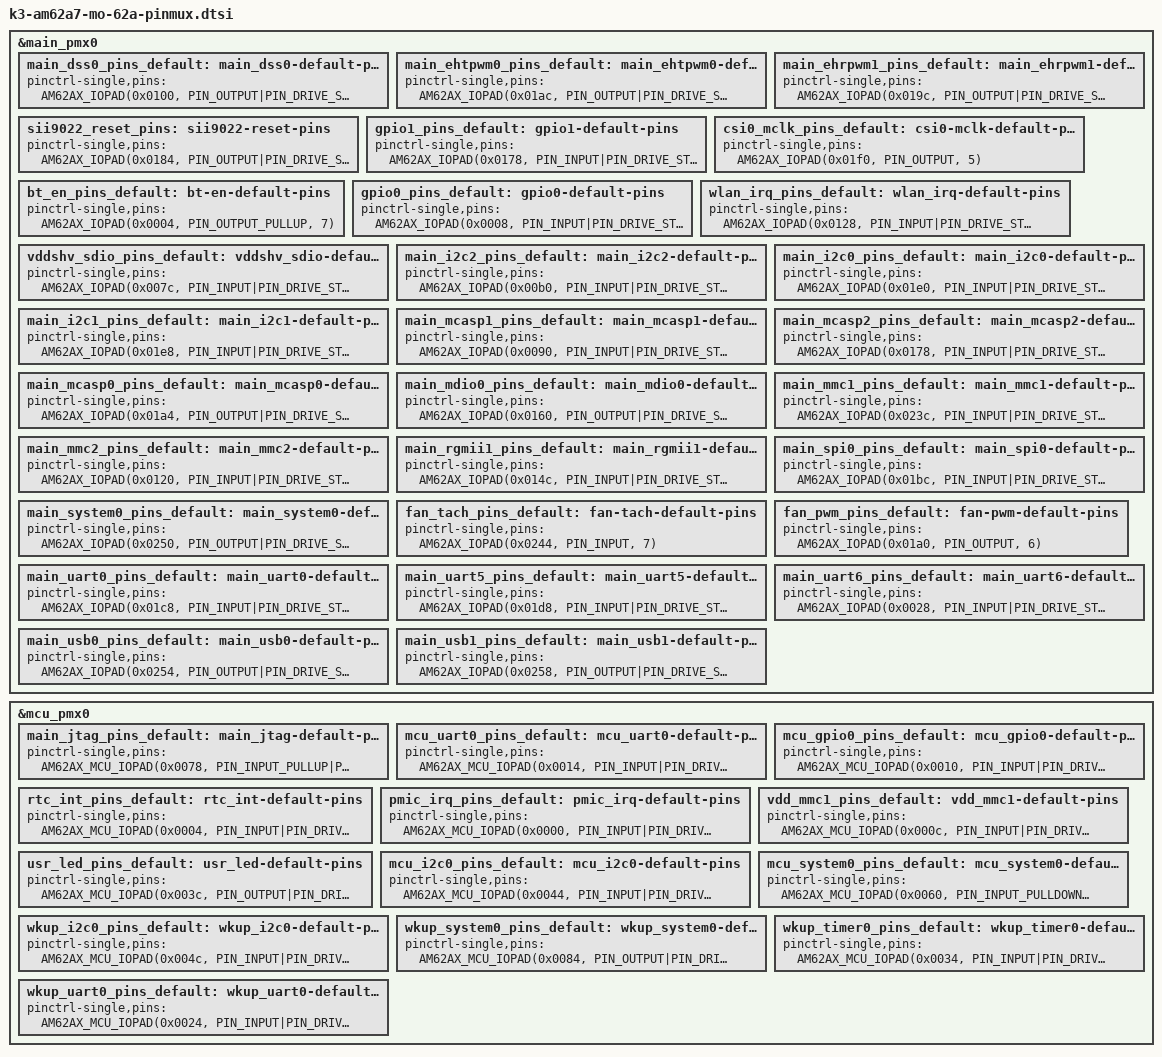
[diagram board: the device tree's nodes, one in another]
/* This file was auto-generated by TI PinMux on 2026/1/26 at 15:44:53. */
/* This file should only be used as a reference. Some pins/peripherals, */
/* depending on your use case, may need additional configuration. */

/* Some or all of the pins from the following groups are not used by the device tree
	main_csi0
	main_ddrss
	mcu_osc0
	main_usb0
	main_usb1
	wkup_lfosc
*/

#ifndef PIN_DRIVE_STRENGTH_NOMINAL
#define PIN_DRIVE_STRENGTH_NOMINAL 0
#endif

&main_pmx0 {
	main_dss0_pins_default: main_dss0-default-pins {
		pinctrl-single,pins = <
			AM62AX_IOPAD(0x0100, PIN_OUTPUT|PIN_DRIVE_STRENGTH_NOMINAL, 0) /* (V17) VOUT0_VSYNC */
			AM62AX_IOPAD(0x00f8, PIN_OUTPUT|PIN_DRIVE_STRENGTH_NOMINAL, 0) /* (T18) VOUT0_HSYNC */
			AM62AX_IOPAD(0x0104, PIN_OUTPUT|PIN_DRIVE_STRENGTH_NOMINAL, 0) /* (AA22) VOUT0_PCLK */
			AM62AX_IOPAD(0x00fc, PIN_OUTPUT|PIN_DRIVE_STRENGTH_NOMINAL, 0) /* (U17) VOUT0_DE */
			AM62AX_IOPAD(0x00b8, PIN_OUTPUT|PIN_DRIVE_STRENGTH_NOMINAL, 0) /* (U22) VOUT0_DATA0 */
			AM62AX_IOPAD(0x00bc, PIN_OUTPUT|PIN_DRIVE_STRENGTH_NOMINAL, 0) /* (U21) VOUT0_DATA1 */
			AM62AX_IOPAD(0x00c0, PIN_OUTPUT|PIN_DRIVE_STRENGTH_NOMINAL, 0) /* (U20) VOUT0_DATA2 */
			AM62AX_IOPAD(0x00c4, PIN_OUTPUT|PIN_DRIVE_STRENGTH_NOMINAL, 0) /* (U19) VOUT0_DATA3 */
			AM62AX_IOPAD(0x00c8, PIN_OUTPUT|PIN_DRIVE_STRENGTH_NOMINAL, 0) /* (T19) VOUT0_DATA4 */
			AM62AX_IOPAD(0x00cc, PIN_OUTPUT|PIN_DRIVE_STRENGTH_NOMINAL, 0) /* (U18) VOUT0_DATA5 */
			AM62AX_IOPAD(0x00d0, PIN_OUTPUT|PIN_DRIVE_STRENGTH_NOMINAL, 0) /* (V22) VOUT0_DATA6 */
			AM62AX_IOPAD(0x00d4, PIN_OUTPUT|PIN_DRIVE_STRENGTH_NOMINAL, 0) /* (V21) VOUT0_DATA7 */
			AM62AX_IOPAD(0x00d8, PIN_OUTPUT|PIN_DRIVE_STRENGTH_NOMINAL, 0) /* (V19) VOUT0_DATA8 */
			AM62AX_IOPAD(0x00dc, PIN_OUTPUT|PIN_DRIVE_STRENGTH_NOMINAL, 0) /* (V18) VOUT0_DATA9 */
			AM62AX_IOPAD(0x00e0, PIN_OUTPUT|PIN_DRIVE_STRENGTH_NOMINAL, 0) /* (W22) VOUT0_DATA10 */
			AM62AX_IOPAD(0x00e4, PIN_OUTPUT|PIN_DRIVE_STRENGTH_NOMINAL, 0) /* (W21) VOUT0_DATA11 */
			AM62AX_IOPAD(0x00e8, PIN_OUTPUT|PIN_DRIVE_STRENGTH_NOMINAL, 0) /* (W20) VOUT0_DATA12 */
			AM62AX_IOPAD(0x00ec, PIN_OUTPUT|PIN_DRIVE_STRENGTH_NOMINAL, 0) /* (W19) VOUT0_DATA13 */
			AM62AX_IOPAD(0x00f0, PIN_OUTPUT|PIN_DRIVE_STRENGTH_NOMINAL, 0) /* (Y21) VOUT0_DATA14 */
			AM62AX_IOPAD(0x00f4, PIN_OUTPUT|PIN_DRIVE_STRENGTH_NOMINAL, 0) /* (Y22) VOUT0_DATA15 */
			AM62AX_IOPAD(0x005c, PIN_OUTPUT|PIN_DRIVE_STRENGTH_NOMINAL, 1) /* (P22) GPMC0_AD8.VOUT0_DATA16 */
			AM62AX_IOPAD(0x0060, PIN_OUTPUT|PIN_DRIVE_STRENGTH_NOMINAL, 1) /* (R19) GPMC0_AD9.VOUT0_DATA17 */
			AM62AX_IOPAD(0x0064, PIN_OUTPUT|PIN_DRIVE_STRENGTH_NOMINAL, 1) /* (R20) GPMC0_AD10.VOUT0_DATA18 */
			AM62AX_IOPAD(0x0068, PIN_OUTPUT|PIN_DRIVE_STRENGTH_NOMINAL, 1) /* (R22) GPMC0_AD11.VOUT0_DATA19 */
			AM62AX_IOPAD(0x006c, PIN_OUTPUT|PIN_DRIVE_STRENGTH_NOMINAL, 1) /* (T22) GPMC0_AD12.VOUT0_DATA20 */
			AM62AX_IOPAD(0x0070, PIN_OUTPUT|PIN_DRIVE_STRENGTH_NOMINAL, 1) /* (R21) GPMC0_AD13.VOUT0_DATA21 */
			AM62AX_IOPAD(0x0074, PIN_OUTPUT|PIN_DRIVE_STRENGTH_NOMINAL, 1) /* (T20) GPMC0_AD14.VOUT0_DATA22 */
			AM62AX_IOPAD(0x0078, PIN_OUTPUT|PIN_DRIVE_STRENGTH_NOMINAL, 1) /* (T21) GPMC0_AD15.VOUT0_DATA23 */
		>;
	};
	main_ehtpwm0_pins_default: main_ehtpwm0-default-pins {
		pinctrl-single,pins = <
			AM62AX_IOPAD(0x01ac, PIN_OUTPUT|PIN_DRIVE_STRENGTH_NOMINAL, 6) /* (B21) MCASP0_AFSR.EHRPWM0_A — EXP Pin33 BCM_GPIO13 */
			AM62AX_IOPAD(0x01b0, PIN_OUTPUT|PIN_DRIVE_STRENGTH_NOMINAL, 6) /* (A21) MCASP0_ACLKR.EHRPWM0_B — EXP Pin32 BCM_GPIO12 */
		>;
	};
	main_ehrpwm1_pins_default: main_ehrpwm1-default-pins {
		pinctrl-single,pins = <
			AM62AX_IOPAD(0x019c, PIN_OUTPUT|PIN_DRIVE_STRENGTH_NOMINAL, 6) /* (B18) MCASP0_AXR1.EHRPWM1_A — EXP Pin36 BCM_GPIO16 */
		>;
	};
	sii9022_reset_pins: sii9022-reset-pins {
		pinctrl-single,pins = <
			AM62AX_IOPAD(0x0184, PIN_OUTPUT|PIN_DRIVE_STRENGTH_NOMINAL, 7) /* (AA21) RGMII2_RD0.GPIO1_3 HDMI_RSTn */
		>;
	};
	gpio1_pins_default: gpio1-default-pins {
		pinctrl-single,pins = <
			AM62AX_IOPAD(0x0178, PIN_INPUT|PIN_DRIVE_STRENGTH_NOMINAL, 7) /* (W17) RGMII2_TD3.GPIO1_0 — EXP Pin12 BCM_GPIO18 (MCASP2_ACLKX) */
			AM62AX_IOPAD(0x017c, PIN_INPUT|PIN_DRIVE_STRENGTH_NOMINAL, 7) /* (W18) RGMII2_RX_CTL.GPIO1_1 AUD_RSTn */
			AM62AX_IOPAD(0x0180, PIN_INPUT|PIN_DRIVE_STRENGTH_NOMINAL, 7) /* (AA20) RGMII2_RXC.GPIO1_2 — EXP Pin40 BCM_GPIO21 (MCASP2_AXR1) */
			AM62AX_IOPAD(0x0188, PIN_INPUT|PIN_DRIVE_STRENGTH_NOMINAL, 7) /* (Y20) RGMII2_RD1.GPIO1_4 */
			AM62AX_IOPAD(0x018c, PIN_INPUT|PIN_DRIVE_STRENGTH_NOMINAL, 7) /* (AB21) RGMII2_RD2.GPIO1_5 — EXP Pin38 BCM_GPIO20 (MCASP2_AXR0) */
			AM62AX_IOPAD(0x0190, PIN_INPUT|PIN_DRIVE_STRENGTH_NOMINAL, 7) /* (AB20) RGMII2_RD3.GPIO1_6 ETHINTn */
			AM62AX_IOPAD(0x0194, PIN_INPUT|PIN_DRIVE_STRENGTH_NOMINAL, 7) /* (C19) MCASP0_AXR3.GPIO1_7 EEP_WC */
			AM62AX_IOPAD(0x019c, PIN_INPUT|PIN_DRIVE_STRENGTH_NOMINAL, 7) /* (B18) MCASP0_AXR1.GPIO1_9 — EXP Pin36 BCM_GPIO16 (EHRPWM1_A) */
			AM62AX_IOPAD(0x01ac, PIN_INPUT|PIN_DRIVE_STRENGTH_NOMINAL, 7) /* (B21) MCASP0_AFSR.GPIO1_13 — EXP Pin33 BCM_GPIO13 (EHRPWM0_A) */
			AM62AX_IOPAD(0x01b0, PIN_INPUT|PIN_DRIVE_STRENGTH_NOMINAL, 7) /* (A21) MCASP0_ACLKR.GPIO1_14 — EXP Pin32 BCM_GPIO12 (EHRPWM0_B) */
			AM62AX_IOPAD(0x01b4, PIN_INPUT|PIN_DRIVE_STRENGTH_NOMINAL, 7) /* (D16) SPI0_CS0.GPIO1_15 — EXP Pin24 BCM_GPIO8 (SPI0_CE0) */
			AM62AX_IOPAD(0x01b8, PIN_INPUT|PIN_DRIVE_STRENGTH_NOMINAL, 7) /* (C16) SPI0_CS1.GPIO1_16 — EXP Pin26 BCM_GPIO7 (SPI0_CE1) */
			AM62AX_IOPAD(0x01bc, PIN_INPUT|PIN_DRIVE_STRENGTH_NOMINAL, 7) /* (A17) SPI0_CLK.GPIO1_17 — EXP Pin23 BCM_GPIO11 (SPI0_CLK) */
			AM62AX_IOPAD(0x01c0, PIN_INPUT|PIN_DRIVE_STRENGTH_NOMINAL, 7) /* (B15) SPI0_D0.GPIO1_18 — EXP Pin19 BCM_GPIO10 (SPI0_MOSI) */
			AM62AX_IOPAD(0x01c4, PIN_INPUT|PIN_DRIVE_STRENGTH_NOMINAL, 7) /* (E15) SPI0_D1.GPIO1_19 — EXP Pin21 BCM_GPIO9 (SPI0_MISO) */
			AM62AX_IOPAD(0x01d0, PIN_INPUT|PIN_DRIVE_STRENGTH_NOMINAL, 7) /* (F14) UART0_CTSn.GPIO1_22 — EXP Pin15 BCM_GPIO22 */
			AM62AX_IOPAD(0x01d4, PIN_INPUT|PIN_DRIVE_STRENGTH_NOMINAL, 7) /* (C15) UART0_RTSn.GPIO1_23 — EXP Pin11 BCM_GPIO23 */
			AM62AX_IOPAD(0x01d8, PIN_INPUT|PIN_DRIVE_STRENGTH_NOMINAL, 7) /* (B17) MCAN0_TX.GPIO1_24 — EXP Pin10 BCM_GPIO15 (UART5_RXD) */
			AM62AX_IOPAD(0x01dc, PIN_INPUT|PIN_DRIVE_STRENGTH_NOMINAL, 7) /* (C18) MCAN0_RX.GPIO1_25 — EXP Pin8 BCM_GPIO14 (UART5_TXD) */
			AM62AX_IOPAD(0x01f4, PIN_INPUT|PIN_DRIVE_STRENGTH_NOMINAL, 7) /* (F17) EXTINTn.GPIO1_31 */
		>;
	};
	csi0_mclk_pins_default: csi0-mclk-default-pins {
		pinctrl-single,pins = <
			AM62AX_IOPAD(0x01f0, PIN_OUTPUT, 5) /* (B16) EXT_REFCLK1.CLKOUT0 for IMX219 MCLK @24MHz */
		>;
	};
	bt_en_pins_default: bt-en-default-pins {
		pinctrl-single,pins = <
			AM62AX_IOPAD(0x0004, PIN_OUTPUT_PULLUP, 7) /* (K22) OSPI0_LBCLKO.GPIO0_1 BT_EN */
		>;
	};
	gpio0_pins_default: gpio0-default-pins {
		pinctrl-single,pins = <
			AM62AX_IOPAD(0x0008, PIN_INPUT|PIN_DRIVE_STRENGTH_NOMINAL, 7) /* (L21) OSPI0_DQS.GPIO0_2 */
			AM62AX_IOPAD(0x002c, PIN_INPUT|PIN_DRIVE_STRENGTH_NOMINAL, 7) /* (H21) OSPI0_CSn0.GPIO0_11 */
			AM62AX_IOPAD(0x0030, PIN_INPUT|PIN_DRIVE_STRENGTH_NOMINAL, 7) /* (G19) OSPI0_CSn1.GPIO0_12 */
			AM62AX_IOPAD(0x0038, PIN_INPUT|PIN_DRIVE_STRENGTH_NOMINAL, 7) /* (G20) OSPI0_CSn3.GPIO0_14 — EXP Pin22 BCM_GPIO25 */
			AM62AX_IOPAD(0x0088, PIN_INPUT|PIN_DRIVE_STRENGTH_NOMINAL, 7) /* (L17) GPMC0_OEn_REn.GPIO0_33 — EXP Pin31 BCM_GPIO6 */
			AM62AX_IOPAD(0x0094, PIN_INPUT|PIN_DRIVE_STRENGTH_NOMINAL, 7) /* (M18) GPMC0_BE1n.GPIO0_36 — EXP Pin29 BCM_GPIO5 */
			AM62AX_IOPAD(0x009c, PIN_INPUT|PIN_DRIVE_STRENGTH_NOMINAL, 7) /* (R17) GPMC0_WAIT1.GPIO0_38 — EXP Pin16 BCM_GPIO17 */
			AM62AX_IOPAD(0x00a0, PIN_INPUT|PIN_DRIVE_STRENGTH_NOMINAL, 7) /* (K17) GPMC0_WPn.GPIO0_39 — EXP Pin7 BCM_GPIO4 */
			AM62AX_IOPAD(0x00a4, PIN_INPUT|PIN_DRIVE_STRENGTH_NOMINAL, 7) /* (K18) GPMC0_DIR.GPIO0_40 — EXP Pin18 BCM_GPIO24 */
			AM62AX_IOPAD(0x00a8, PIN_INPUT|PIN_DRIVE_STRENGTH_NOMINAL, 7) /* (M19) GPMC0_CSn0.GPIO0_41 — EXP Pin37 BCM_GPIO26 */
			AM62AX_IOPAD(0x00ac, PIN_INPUT|PIN_DRIVE_STRENGTH_NOMINAL, 7) /* (M21) GPMC0_CSn1.GPIO0_42 — EXP Pin13 BCM_GPIO27 */
			AM62AX_IOPAD(0x0164, PIN_INPUT|PIN_DRIVE_STRENGTH_NOMINAL, 7) /* (Y19) RGMII2_TX_CTL.GPIO0_87 CSI0_XSHUTDOWN */
			AM62AX_IOPAD(0x0168, PIN_OUTPUT_PULLDOWN, 7) /* (AB19) RGMII2_TXC.GPIO0_88 EXP_3V3_EN */
			AM62AX_IOPAD(0x016c, PIN_INPUT|PIN_DRIVE_STRENGTH_NOMINAL, 7) /* (AA19) RGMII2_TD0.GPIO0_89 */
			AM62AX_IOPAD(0x0170, PIN_INPUT|PIN_DRIVE_STRENGTH_NOMINAL, 7) /* (Y18) RGMII2_TD1.GPIO0_90 SiI9022_INT */
			AM62AX_IOPAD(0x0174, PIN_INPUT|PIN_DRIVE_STRENGTH_NOMINAL, 7) /* (AA18) RGMII2_TD2.GPIO0_91 — EXP Pin35 BCM_GPIO19 (MCASP2_AFSX) */
		>;
	};
	wlan_irq_pins_default: wlan_irq-default-pins {
		pinctrl-single,pins = <
			AM62AX_IOPAD(0x0128, PIN_INPUT|PIN_DRIVE_STRENGTH_NOMINAL, 7) /* (E21) MMC2_SDWP.GPIO0_72 */
		>;
	};
	vddshv_sdio_pins_default: vddshv_sdio-default-pins {
		pinctrl-single,pins = <
			AM62AX_IOPAD(0x007c, PIN_INPUT|PIN_DRIVE_STRENGTH_NOMINAL, 7) /* (N22) GPMC0_CLK.GPIO0_31 */
		>;
	};
	main_i2c2_pins_default: main_i2c2-default-pins {
		pinctrl-single,pins = <
			AM62AX_IOPAD(0x00b0, PIN_INPUT|PIN_DRIVE_STRENGTH_NOMINAL, 1) /* (M22) GPMC0_CSn2.I2C2_SCL */
			AM62AX_IOPAD(0x00b4, PIN_INPUT|PIN_DRIVE_STRENGTH_NOMINAL, 1) /* (M20) GPMC0_CSn3.I2C2_SDA */
		>;
	};
	main_i2c0_pins_default: main_i2c0-default-pins {
		pinctrl-single,pins = <
			AM62AX_IOPAD(0x01e0, PIN_INPUT|PIN_DRIVE_STRENGTH_NOMINAL, 0) /* (D17) I2C0_SCL */
			AM62AX_IOPAD(0x01e4, PIN_INPUT|PIN_DRIVE_STRENGTH_NOMINAL, 0) /* (E16) I2C0_SDA */
		>;
	};
	main_i2c1_pins_default: main_i2c1-default-pins {
		pinctrl-single,pins = <
			AM62AX_IOPAD(0x01e8, PIN_INPUT|PIN_DRIVE_STRENGTH_NOMINAL, 0) /* (C17) I2C1_SCL */
			AM62AX_IOPAD(0x01ec, PIN_INPUT|PIN_DRIVE_STRENGTH_NOMINAL, 0) /* (E17) I2C1_SDA */
		>;
	};
	main_mcasp1_pins_default: main_mcasp1-default-pins {
		pinctrl-single,pins = <
			AM62AX_IOPAD(0x0090, PIN_INPUT|PIN_DRIVE_STRENGTH_NOMINAL, 2) /* (L19) GPMC0_BE0n_CLE.MCASP1_ACLKX */
			AM62AX_IOPAD(0x0098, PIN_INPUT|PIN_DRIVE_STRENGTH_NOMINAL, 2) /* (R18) GPMC0_WAIT0.MCASP1_AFSX */
			AM62AX_IOPAD(0x008c, PIN_INPUT|PIN_DRIVE_STRENGTH_NOMINAL, 2) /* (K19) GPMC0_WEn.MCASP1_AXR0 */
			AM62AX_IOPAD(0x0084, PIN_INPUT|PIN_DRIVE_STRENGTH_NOMINAL, 2) /* (L18) GPMC0_ADVn_ALE.MCASP1_AXR2 */
		>;
	};
	main_mcasp2_pins_default: main_mcasp2-default-pins {
		pinctrl-single,pins = <
			AM62AX_IOPAD(0x0178, PIN_INPUT|PIN_DRIVE_STRENGTH_NOMINAL, 2) /* (W17) RGMII2_TD3.MCASP2_ACLKX */
			AM62AX_IOPAD(0x0174, PIN_INPUT|PIN_DRIVE_STRENGTH_NOMINAL, 2) /* (AA18) RGMII2_TD2.MCASP2_AFSX */
			AM62AX_IOPAD(0x018c, PIN_INPUT|PIN_DRIVE_STRENGTH_NOMINAL, 2) /* (AB21) RGMII2_RD2.MCASP2_AXR0 */
			AM62AX_IOPAD(0x0180, PIN_INPUT|PIN_DRIVE_STRENGTH_NOMINAL, 2) /* (AA20) RGMII2_RXC.MCASP2_AXR1 */
		>;
	};
	main_mcasp0_pins_default: main_mcasp0-default-pins {
		pinctrl-single,pins = <
			AM62AX_IOPAD(0x01a4, PIN_OUTPUT|PIN_DRIVE_STRENGTH_NOMINAL, 0) /* (A19) MCASP0_ACLKX master */
			AM62AX_IOPAD(0x01a8, PIN_OUTPUT|PIN_DRIVE_STRENGTH_NOMINAL, 0) /* (A20) MCASP0_AFSX master */
			AM62AX_IOPAD(0x0198, PIN_OUTPUT|PIN_DRIVE_STRENGTH_NOMINAL, 0) /* (B19) MCASP0_AXR2 TX to SiI9022 */
		>;
	};
	main_mdio0_pins_default: main_mdio0-default-pins {
		pinctrl-single,pins = <
			AM62AX_IOPAD(0x0160, PIN_OUTPUT|PIN_DRIVE_STRENGTH_NOMINAL, 0) /* (V12) MDIO0_MDC */
			AM62AX_IOPAD(0x015c, PIN_INPUT|PIN_DRIVE_STRENGTH_NOMINAL, 0) /* (V13) MDIO0_MDIO */
		>;
	};
	main_mmc1_pins_default: main_mmc1-default-pins {
		pinctrl-single,pins = <
			AM62AX_IOPAD(0x023c, PIN_INPUT|PIN_DRIVE_STRENGTH_NOMINAL, 0) /* (C21) MMC1_CMD */
			AM62AX_IOPAD(0x0234, PIN_OUTPUT|PIN_DRIVE_STRENGTH_NOMINAL, 0) /* (E22) MMC1_CLK */
			AM62AX_IOPAD(0x0230, PIN_INPUT|PIN_DRIVE_STRENGTH_NOMINAL, 0) /* (B22) MMC1_DAT0 */
			AM62AX_IOPAD(0x022c, PIN_INPUT|PIN_DRIVE_STRENGTH_NOMINAL, 0) /* (D21) MMC1_DAT1 */
			AM62AX_IOPAD(0x0228, PIN_INPUT|PIN_DRIVE_STRENGTH_NOMINAL, 0) /* (C22) MMC1_DAT2 */
			AM62AX_IOPAD(0x0224, PIN_INPUT|PIN_DRIVE_STRENGTH_NOMINAL, 0) /* (D22) MMC1_DAT3 */
			AM62AX_IOPAD(0x0240, PIN_INPUT|PIN_DRIVE_STRENGTH_NOMINAL, 0) /* (E18) MMC1_SDCD */
		>;
	};
	main_mmc2_pins_default: main_mmc2-default-pins {
		pinctrl-single,pins = <
			AM62AX_IOPAD(0x0120, PIN_INPUT|PIN_DRIVE_STRENGTH_NOMINAL, 0) /* (G22) MMC2_CMD */
			AM62AX_IOPAD(0x0118, PIN_OUTPUT|PIN_DRIVE_STRENGTH_NOMINAL, 0) /* (H22) MMC2_CLK */
			AM62AX_IOPAD(0x011C, PIN_INPUT, 0) /* () MMC2_CLKLB */
			AM62AX_IOPAD(0x0114, PIN_INPUT|PIN_DRIVE_STRENGTH_NOMINAL, 0) /* (E20) MMC2_DAT0 */
			AM62AX_IOPAD(0x0110, PIN_INPUT|PIN_DRIVE_STRENGTH_NOMINAL, 0) /* (F21) MMC2_DAT1 */
			AM62AX_IOPAD(0x010c, PIN_INPUT|PIN_DRIVE_STRENGTH_NOMINAL, 0) /* (F20) MMC2_DAT2 */
			AM62AX_IOPAD(0x0108, PIN_INPUT|PIN_DRIVE_STRENGTH_NOMINAL, 0) /* (G21) MMC2_DAT3 */
		>;
	};
	main_rgmii1_pins_default: main_rgmii1-default-pins {
		pinctrl-single,pins = <
			AM62AX_IOPAD(0x014c, PIN_INPUT|PIN_DRIVE_STRENGTH_NOMINAL, 0) /* (AB16) RGMII1_RD0 */
			AM62AX_IOPAD(0x0150, PIN_INPUT|PIN_DRIVE_STRENGTH_NOMINAL, 0) /* (V15) RGMII1_RD1 */
			AM62AX_IOPAD(0x0154, PIN_INPUT|PIN_DRIVE_STRENGTH_NOMINAL, 0) /* (W15) RGMII1_RD2 */
			AM62AX_IOPAD(0x0158, PIN_INPUT|PIN_DRIVE_STRENGTH_NOMINAL, 0) /* (V14) RGMII1_RD3 */
			AM62AX_IOPAD(0x0148, PIN_INPUT|PIN_DRIVE_STRENGTH_NOMINAL, 0) /* (AA16) RGMII1_RXC */
			AM62AX_IOPAD(0x0144, PIN_INPUT|PIN_DRIVE_STRENGTH_NOMINAL, 0) /* (AA15) RGMII1_RX_CTL */
			AM62AX_IOPAD(0x0134, PIN_OUTPUT|PIN_DRIVE_STRENGTH_NOMINAL, 0) /* (Y17) RGMII1_TD0 */
			AM62AX_IOPAD(0x0138, PIN_OUTPUT|PIN_DRIVE_STRENGTH_NOMINAL, 0) /* (V16) RGMII1_TD1 */
			AM62AX_IOPAD(0x013c, PIN_OUTPUT|PIN_DRIVE_STRENGTH_NOMINAL, 0) /* (Y16) RGMII1_TD2 */
			AM62AX_IOPAD(0x0140, PIN_OUTPUT|PIN_DRIVE_STRENGTH_NOMINAL, 0) /* (AA17) RGMII1_TD3 */
			AM62AX_IOPAD(0x0130, PIN_OUTPUT|PIN_DRIVE_STRENGTH_NOMINAL, 0) /* (AB17) RGMII1_TXC */
			AM62AX_IOPAD(0x012c, PIN_OUTPUT|PIN_DRIVE_STRENGTH_NOMINAL, 0) /* (W16) RGMII1_TX_CTL */
		>;
	};
	main_spi0_pins_default: main_spi0-default-pins {
		pinctrl-single,pins = <
			AM62AX_IOPAD(0x01bc, PIN_INPUT|PIN_DRIVE_STRENGTH_NOMINAL, 0) /* (A17) SPI0_CLK */
			AM62AX_IOPAD(0x01b4, PIN_INPUT|PIN_DRIVE_STRENGTH_NOMINAL, 0) /* (D16) SPI0_CS0 */
			AM62AX_IOPAD(0x01b8, PIN_INPUT|PIN_DRIVE_STRENGTH_NOMINAL, 0) /* (C16) SPI0_CS1 */
			AM62AX_IOPAD(0x01c0, PIN_INPUT|PIN_DRIVE_STRENGTH_NOMINAL, 0) /* (B15) SPI0_D0 */
			AM62AX_IOPAD(0x01c4, PIN_INPUT|PIN_DRIVE_STRENGTH_NOMINAL, 0) /* (E15) SPI0_D1 */
		>;
	};
	main_system0_pins_default: main_system0-default-pins {
		pinctrl-single,pins = <
			/* 0x00a0 GPMC0_WPn removed — reassigned to GPIO0_39 (EXP Pin7 BCM_GPIO4) */
			AM62AX_IOPAD(0x0250, PIN_OUTPUT|PIN_DRIVE_STRENGTH_NOMINAL, 0) /* (F18) PORz_OUT */
			AM62AX_IOPAD(0x024c, PIN_OUTPUT|PIN_DRIVE_STRENGTH_NOMINAL, 0) /* (F19) RESETSTATz */
			AM62AX_IOPAD(0x0248, PIN_INPUT_PULLUP|PIN_DRIVE_STRENGTH_NOMINAL, 0) /* (E19) RESET_REQz */
		>;
	};
	fan_tach_pins_default: fan-tach-default-pins {
		pinctrl-single,pins = <
			AM62AX_IOPAD(0x0244, PIN_INPUT, 7) /* (D18) MMC1_SDWP.GPIO1_49 -> FAN_TACH, pull-up via R79 4.7K on A-side */
		>;
	};

	fan_pwm_pins_default: fan-pwm-default-pins {
		pinctrl-single,pins = <
			AM62AX_IOPAD(0x01a0, PIN_OUTPUT, 6) /* (B20) MCASP0_AXR0.EHRPWM1_B -> FAN_PWM */
		>;
	};
	main_uart0_pins_default: main_uart0-default-pins {
		pinctrl-single,pins = <
			AM62AX_IOPAD(0x01c8, PIN_INPUT|PIN_DRIVE_STRENGTH_NOMINAL, 0) /* (E14) UART0_RXD */
			AM62AX_IOPAD(0x01cc, PIN_OUTPUT|PIN_DRIVE_STRENGTH_NOMINAL, 0) /* (D15) UART0_TXD */
		>;
	};
	main_uart5_pins_default: main_uart5-default-pins {
		pinctrl-single,pins = <
			AM62AX_IOPAD(0x01d8, PIN_INPUT|PIN_DRIVE_STRENGTH_NOMINAL, 1) /* (B17) MCAN0_TX.UART5_RXD */
			AM62AX_IOPAD(0x01dc, PIN_OUTPUT_PULLUP|PIN_DRIVE_STRENGTH_NOMINAL, 1) /* (C18) MCAN0_RX.UART5_TXD */
		>;
	};
	main_uart6_pins_default: main_uart6-default-pins {
		pinctrl-single,pins = <
			AM62AX_IOPAD(0x0028, PIN_INPUT|PIN_DRIVE_STRENGTH_NOMINAL, 3) /* (J22) OSPI0_D7.UART6_CTSn */
			AM62AX_IOPAD(0x0024, PIN_OUTPUT|PIN_DRIVE_STRENGTH_NOMINAL, 3) /* (J20) OSPI0_D6.UART6_RTSn */
			AM62AX_IOPAD(0x001c, PIN_INPUT|PIN_DRIVE_STRENGTH_NOMINAL, 3) /* (K21) OSPI0_D4.UART6_RXD */
			AM62AX_IOPAD(0x0020, PIN_OUTPUT|PIN_DRIVE_STRENGTH_NOMINAL, 3) /* (H19) OSPI0_D5.UART6_TXD */
		>;
	};
	main_usb0_pins_default: main_usb0-default-pins {
		pinctrl-single,pins = <
			AM62AX_IOPAD(0x0254, PIN_OUTPUT|PIN_DRIVE_STRENGTH_NOMINAL, 0) /* (C20) USB0_DRVVBUS */
		>;
	};
	main_usb1_pins_default: main_usb1-default-pins {
		pinctrl-single,pins = <
			AM62AX_IOPAD(0x0258, PIN_OUTPUT|PIN_DRIVE_STRENGTH_NOMINAL, 0) /* (D19) USB1_DRVVBUS */
		>;
	};
};


&mcu_pmx0 {
	main_jtag_pins_default: main_jtag-default-pins {
		pinctrl-single,pins = <
			AM62AX_MCU_IOPAD(0x0078, PIN_INPUT_PULLUP|PIN_DRIVE_STRENGTH_NOMINAL, 0) /* (C13) EMU0 */
			AM62AX_MCU_IOPAD(0x007c, PIN_INPUT_PULLUP|PIN_DRIVE_STRENGTH_NOMINAL, 0) /* (E10) EMU1 */
			AM62AX_MCU_IOPAD(0x0064, PIN_INPUT_PULLUP|PIN_DRIVE_STRENGTH_NOMINAL, 0) /* (A14) TCK */
			AM62AX_MCU_IOPAD(0x006c, PIN_INPUT_PULLUP|PIN_DRIVE_STRENGTH_NOMINAL, 0) /* (A16) TDI */
			AM62AX_MCU_IOPAD(0x0070, PIN_OUTPUT_PULLUP|PIN_DRIVE_STRENGTH_NOMINAL, 0) /* (C14) TDO */
			AM62AX_MCU_IOPAD(0x0074, PIN_INPUT_PULLUP|PIN_DRIVE_STRENGTH_NOMINAL, 0) /* (B14) TMS */
			AM62AX_MCU_IOPAD(0x0068, PIN_INPUT_PULLDOWN|PIN_DRIVE_STRENGTH_NOMINAL, 0) /* (F15) TRSTn */
		>;
	};
	mcu_uart0_pins_default: mcu_uart0-default-pins {
		pinctrl-single,pins = <
			AM62AX_MCU_IOPAD(0x0014, PIN_INPUT|PIN_DRIVE_STRENGTH_NOMINAL, 0) /* (D8) MCU_UART0_RXD */
			AM62AX_MCU_IOPAD(0x0018, PIN_OUTPUT|PIN_DRIVE_STRENGTH_NOMINAL, 0) /* (F8) MCU_UART0_TXD */
		>;
	};
	mcu_gpio0_pins_default: mcu_gpio0-default-pins {
		pinctrl-single,pins = <
			AM62AX_MCU_IOPAD(0x0010, PIN_INPUT|PIN_DRIVE_STRENGTH_NOMINAL, 7) /* (B12) MCU_SPI0_D1.MCU_GPIO0_4 */
			AM62AX_MCU_IOPAD(0x004c, PIN_INPUT|PIN_DRIVE_STRENGTH_NOMINAL, 7) /* (D13) WKUP_I2C0_SCL.MCU_GPIO0_19 — EXP Pin5 BCM_GPIO3 (WKUP_I2C0_SCL) */
			AM62AX_MCU_IOPAD(0x0050, PIN_INPUT|PIN_DRIVE_STRENGTH_NOMINAL, 7) /* (E13) WKUP_I2C0_SDA.MCU_GPIO0_20 — EXP Pin3 BCM_GPIO2 (WKUP_I2C0_SDA) */
		>;
	};
	rtc_int_pins_default: rtc_int-default-pins {
		pinctrl-single,pins = <
			AM62AX_MCU_IOPAD(0x0004, PIN_INPUT|PIN_DRIVE_STRENGTH_NOMINAL, 7) /* (C11) MCU_SPI0_CS1.MCU_GPIO0_1 */
		>;
	};
	pmic_irq_pins_default: pmic_irq-default-pins {
		pinctrl-single,pins = <
			AM62AX_MCU_IOPAD(0x0000, PIN_INPUT|PIN_DRIVE_STRENGTH_NOMINAL, 7) /* (E11) MCU_SPI0_CS0.MCU_GPIO0_0 */
		>;
	};
	vdd_mmc1_pins_default: vdd_mmc1-default-pins {
		pinctrl-single,pins = <
			AM62AX_MCU_IOPAD(0x000c, PIN_INPUT|PIN_DRIVE_STRENGTH_NOMINAL, 7) /* (A15) MCU_SPI0_D0.MCU_GPIO0_3 */
		>;
	};
	usr_led_pins_default: usr_led-default-pins {
		pinctrl-single,pins = <
			AM62AX_MCU_IOPAD(0x003c, PIN_OUTPUT|PIN_DRIVE_STRENGTH_NOMINAL, 7) /* (D7) MCU_MCAN1_TX.MCU_GPIO0_15 -> GREEN_LED */
			AM62AX_MCU_IOPAD(0x0040, PIN_OUTPUT|PIN_DRIVE_STRENGTH_NOMINAL, 7) /* (B9) MCU_MCAN1_RX.MCU_GPIO0_16 -> RED_LED */
		>;
	};
	mcu_i2c0_pins_default: mcu_i2c0-default-pins {
		pinctrl-single,pins = <
			AM62AX_MCU_IOPAD(0x0044, PIN_INPUT|PIN_DRIVE_STRENGTH_NOMINAL, 0) /* (E12) MCU_I2C0_SCL */
			AM62AX_MCU_IOPAD(0x0048, PIN_INPUT|PIN_DRIVE_STRENGTH_NOMINAL, 0) /* (D9) MCU_I2C0_SDA */
		>;
	};
	mcu_system0_pins_default: mcu_system0-default-pins {
		pinctrl-single,pins = <
			AM62AX_MCU_IOPAD(0x0060, PIN_INPUT_PULLDOWN|PIN_DRIVE_STRENGTH_NOMINAL, 0) /* (B8) MCU_ERRORn */
			AM62AX_MCU_IOPAD(0x0058, PIN_OUTPUT|PIN_DRIVE_STRENGTH_NOMINAL, 0) /* (A7) MCU_PORz */
			AM62AX_MCU_IOPAD(0x005c, PIN_OUTPUT|PIN_DRIVE_STRENGTH_NOMINAL, 0) /* (D14) MCU_RESETSTATz */
			AM62AX_MCU_IOPAD(0x0054, PIN_INPUT_PULLUP|PIN_DRIVE_STRENGTH_NOMINAL, 0) /* (C12) MCU_RESETz */
		>;
	};
	wkup_i2c0_pins_default: wkup_i2c0-default-pins {
		pinctrl-single,pins = <
			AM62AX_MCU_IOPAD(0x004c, PIN_INPUT|PIN_DRIVE_STRENGTH_NOMINAL, 0) /* (D13) WKUP_I2C0_SCL */
			AM62AX_MCU_IOPAD(0x0050, PIN_INPUT|PIN_DRIVE_STRENGTH_NOMINAL, 0) /* (E13) WKUP_I2C0_SDA */
		>;
	};
	wkup_system0_pins_default: wkup_system0-default-pins {
		pinctrl-single,pins = <
			AM62AX_MCU_IOPAD(0x0084, PIN_OUTPUT|PIN_DRIVE_STRENGTH_NOMINAL, 0) /* (B10) WKUP_CLKOUT0 */
			AM62AX_MCU_IOPAD(0x0080, PIN_OUTPUT|PIN_DRIVE_STRENGTH_NOMINAL, 0) /* (D12) PMIC_LPM_EN0 */
		>;
	};
	wkup_timer0_pins_default: wkup_timer0-default-pins {
		pinctrl-single,pins = <
			AM62AX_MCU_IOPAD(0x0034, PIN_INPUT|PIN_DRIVE_STRENGTH_NOMINAL, 1) /* (C7) MCU_MCAN0_TX.WKUP_TIMER_IO0 */
		>;
	};
	wkup_uart0_pins_default: wkup_uart0-default-pins {
		pinctrl-single,pins = <
			AM62AX_MCU_IOPAD(0x0024, PIN_INPUT|PIN_DRIVE_STRENGTH_NOMINAL, 0) /* (C9) WKUP_UART0_RXD */
			AM62AX_MCU_IOPAD(0x0028, PIN_OUTPUT|PIN_DRIVE_STRENGTH_NOMINAL, 0) /* (E9) WKUP_UART0_TXD */
		>;
	};
};
